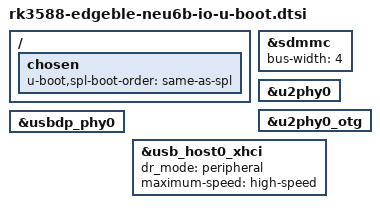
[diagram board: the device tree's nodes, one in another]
// SPDX-License-Identifier: (GPL-2.0+ OR MIT)
/*
 * Copyright (c) 2022 Edgeble AI Technologies Pvt. Ltd.
 */

#include "rk3588j-u-boot.dtsi"

/ {
	chosen {
		u-boot,spl-boot-order = "same-as-spl", &sdhci, &sdmmc;
	};
};

&sdmmc {
	bus-width = <4>;
	status = "okay";
};

&u2phy0 {
	status = "okay";
};

&u2phy0_otg {
	status = "okay";
};

&usbdp_phy0 {
	status = "okay";
};

&usb_host0_xhci {
	dr_mode = "peripheral";
	maximum-speed = "high-speed";
	status = "okay";
};
